AUTOSAR XML (schema 4-2-2)
package /ComponentTypes
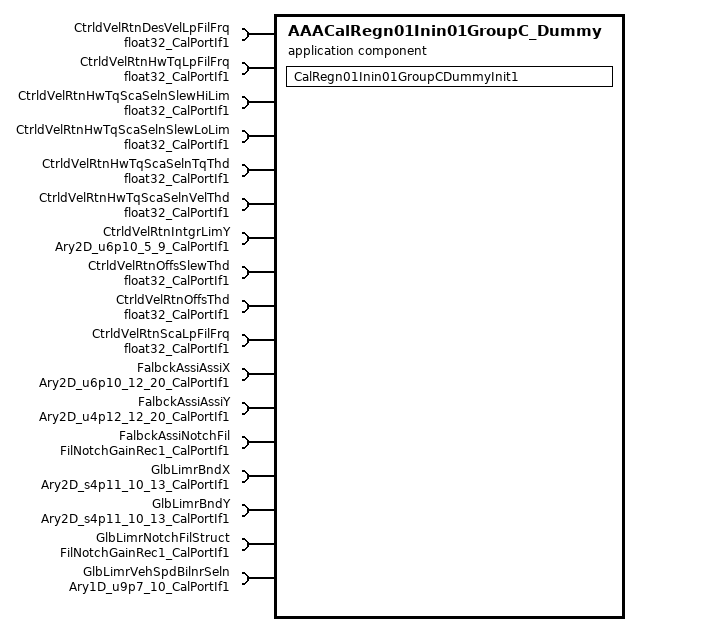
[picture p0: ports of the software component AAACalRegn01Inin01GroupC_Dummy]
  application sw component type AAACalRegn01Inin01GroupC_Dummy
    17 x require port:
      CtrldVelRtnDesVelLpFilFrq: parameter-require-com-spec{init-value=20, parameter=Val}, required-interface=float32_CalPortIf1
      CtrldVelRtnHwTqLpFilFrq: parameter-require-com-spec{init-value=20, parameter=Val}, required-interface=float32_CalPortIf1
      CtrldVelRtnHwTqScaSelnSlewHiLim: parameter-require-com-spec{init-value=500, parameter=Val}, required-interface=float32_CalPortIf1
      CtrldVelRtnHwTqScaSelnSlewLoLim: parameter-require-com-spec{init-value=-500, parameter=Val}, required-interface=float32_CalPortIf1
      CtrldVelRtnHwTqScaSelnTqThd: parameter-require-com-spec{init-value=0, parameter=Val}, required-interface=float32_CalPortIf1
      CtrldVelRtnHwTqScaSelnVelThd: parameter-require-com-spec{init-value=0, parameter=Val}, required-interface=float32_CalPortIf1
      CtrldVelRtnIntgrLimY: parameter-require-com-spec{init-value=[[2048, 5120, 5120, 10240, 10240, 15360, 15360, 20480, 20480], [2048, 5120, 5120, 10240, 10240, 15360, 15360, 20480, 20480], [2048, 5120, 5120, 10240, 10240, 10240, 15360, 15360, 15360], [2048, 5120, 5120, 10240, 10240, 10240, 10240, 10240, 10240], [2048, 5120, 5120, 10240, 10240, 10240, 10240, 10240, 10240]], parameter=Ary2D}, required-interface=Ary2D_u6p10_5_9_CalPortIf1
      CtrldVelRtnOffsSlewThd: parameter-require-com-spec{init-value=0.04, parameter=Val}, required-interface=float32_CalPortIf1
      CtrldVelRtnOffsThd: parameter-require-com-spec{init-value=17, parameter=Val}, required-interface=float32_CalPortIf1
      CtrldVelRtnScaLpFilFrq: parameter-require-com-spec{init-value=20, parameter=Val}, required-interface=float32_CalPortIf1
      FalbckAssiAssiX: parameter-require-com-spec{init-value=[[0, 4, 508, 608, 712, 816, 916, 1020, 1124, 1228, 1328, 1432, 1536, 1636, 1740, 1844, 1944, 2048, 6920, 10240], [0, 204, 716, 792, 868, 944, 1016, 1092, 1168, 1244, 1316, 1392, 1468, 1544, 1616, 1692, 1768, 1844, 9348, 10240], [0, 308, 820, 908, 1000, 1088, 1176, 1268, 1356, 1448, 1536, 1624, 1716, 1804, 1896, 1984, 2072, 2164, 2252, 10240], [0, 192, 1024, 1164, 1304, 1448, 1588, 1728, 1868, 2008, 2152, 2292, 2432, 2572, 2712, 2856, 2996, 3136, 3276, 10240], [0, 176, 836, 1048, 1260, 1472, 1684, 1896, 2108, 2320, 2532, 2744, 2956, 3168, 3380, 3592, 3804, 4016, 4228, 10240], [0, 192, 916, 1148, 1376, 1608, 1840, 2072, 2304, 2536, 2768, 3000, 3232, 3464, 3692, 3924, 4156, 4388, 4620, 10240], [0, 204, 972, 1220, 1464, 1712, 1960, 2204, 2452, 2696, 2944, 3192, 3436, 3684, 3928, 4176, 4424, 4668, 4916, 10240], [0, 216, 1020, 1280, 1540, 1796, 2056, 2316, 2572, 2832, 3092, 3348, 3608, 3868, 4128, 4384, 4644, 4904, 5160, 10240], [0, 244, 1168, 1464, 1760, 2056, 2352, 2644, 2940, 3236, 3532, 3828, 4124, 4420, 4716, 5012, 5308, 5604, 5900, 10240], [0, 308, 1460, 1828, 2200, 2568, 2936, 3308, 3676, 4048, 4416, 4784, 5156, 5524, 5896, 6264, 6632, 7004, 7372, 10240], [0, 4, 1892, 2140, 2596, 2880, 3396, 3640, 4436, 4676, 5200, 5712, 6220, 6748, 7268, 7512, 8024, 8552, 8800, 10240], [0, 4, 1892, 2140, 2596, 2880, 3396, 3640, 4436, 4676, 5200, 5712, 6220, 6748, 7268, 7512, 8024, 8552, 8800, 10240]], parameter=Ary2D}, required-interface=Ary2D_u6p10_12_20_CalPortIf1
      FalbckAssiAssiY: parameter-require-com-spec{init-value=[[0, 0, 40, 58, 98, 159, 242, 343, 470, 615, 782, 972, 1182, 1411, 1663, 1937, 2232, 2546, 18022, 18022], [0, 0, 41, 52, 73, 107, 150, 205, 270, 346, 432, 530, 637, 756, 885, 1025, 1176, 1338, 18022, 18022], [0, 0, 29, 37, 55, 86, 122, 171, 229, 294, 372, 458, 551, 655, 770, 894, 1027, 1169, 1321, 15274], [0, 0, 41, 55, 79, 121, 171, 239, 317, 409, 513, 630, 759, 904, 1059, 1230, 1413, 1607, 1815, 12432], [0, 0, 49, 73, 113, 171, 245, 340, 447, 574, 716, 879, 1053, 1249, 1460, 1688, 1933, 2196, 2473, 10636], [0, 0, 49, 73, 113, 171, 245, 340, 447, 574, 716, 879, 1053, 1249, 1460, 1688, 1933, 2196, 2473, 9452], [0, 0, 49, 73, 113, 171, 245, 340, 447, 574, 716, 879, 1053, 1249, 1460, 1688, 1933, 2196, 2473, 8691], [0, 0, 49, 73, 113, 171, 245, 340, 447, 574, 716, 879, 1053, 1249, 1460, 1688, 1933, 2196, 2473, 8122], [0, 0, 49, 73, 113, 171, 245, 340, 447, 574, 716, 879, 1053, 1249, 1460, 1688, 1933, 2196, 2473, 6697], [0, 0, 49, 73, 113, 171, 245, 340, 447, 574, 716, 879, 1053, 1249, 1460, 1688, 1933, 2196, 2473, 4706], [0, 0, 66, 84, 131, 168, 254, 300, 488, 554, 713, 892, 1090, 1315, 1559, 1681, 1953, 2253, 2404, 3267], [0, 0, 66, 84, 131, 168, 254, 300, 488, 554, 713, 892, 1090, 1315, 1559, 1681, 1953, 2253, 2404, 3267]], parameter=Ary2D}, required-interface=Ary2D_u4p12_12_20_CalPortIf1
      FalbckAssiNotchFil: parameter-require-com-spec=Rec, required-interface=FilNotchGainRec1_CalPortIf1
      GlbLimrBndX: parameter-require-com-spec{init-value=10 x [-20480, -10240, -8192, -6144, -4096, -2048, 0, 2048, 4096, 6144, 8192, 10240, 20480], parameter=Ary2D}, required-interface=Ary2D_s4p11_10_13_CalPortIf1
      GlbLimrBndY: parameter-require-com-spec{init-value=[[-11754, -11754, -10774, -4114, -1959, -196, 1567, 3918, 7836, 17631, 18022, 18022, 18022], [-11754, -11754, -9795, -1959, -784, 196, 784, 1175, 5877, 12537, 15672, 18022, 18022], [-11754, -7836, -3918, -1959, -196, 0, 1175, 2938, 3526, 6269, 18022, 18022, 18022], [-11754, -5877, -4506, 0, 196, 588, 784, 980, 2938, 5093, 7836, 18022, 18022], [0, 0, 0, 392, 588, 588, 784, 2938, 3330, 4114, 5877, 5877, 5877], [0, 784, 784, 784, 784, 784, 784, 2547, 2938, 3526, 5877, 5877, 5877], [0, 784, 784, 784, 784, 784, 784, 2547, 2938, 3526, 5877, 5877, 5877], [0, 784, 784, 784, 784, 784, 784, 2547, 2938, 3526, 5877, 5877, 5877], [0, 784, 784, 784, 784, 784, 784, 2547, 2938, 3526, 5877, 5877, 5877], [0, 784, 784, 784, 784, 784, 784, 2547, 2938, 3526, 5877, 5877, 5877]], parameter=Ary2D}, required-interface=Ary2D_s4p11_10_13_CalPortIf1
      GlbLimrNotchFilStruct: parameter-require-com-spec=Rec, required-interface=FilNotchGainRec1_CalPortIf1
      GlbLimrVehSpdBilnrSeln: parameter-require-com-spec{init-value=[0, 640, 3840, 7680, 10240, 12800, 15360, 19200, 23040, 25600], parameter=Ary1D}, required-interface=Ary1D_u9p7_10_CalPortIf1
    behavior AAACalRegn01Inin01GroupC_Dummy_InternalBehavior: supports-multiple-instantiation=true
      init event AAACalRegn01Inin01GroupC_Dummy_InitEvent: start-on-event=CalRegn01Inin01GroupCDummyInit1
      runnable CalRegn01Inin01GroupCDummyInit1
  swc implementation AAACalRegn01Inin00GroupC_Dummy_Implementation: behavior=AAACalRegn01Inin01GroupC_Dummy_InternalBehavior
    code-descriptors:
      code Default: artifact-descriptors=autosar-engineering-object={short-label=Default, category=SWSRC}
